# STM32F722xx register map
File version: 1.0
Registers are 32-bit, read-write, reset 0x0 unless marked. A register's access mark holds for its fields unless they carry their own. Offsets are from the block's base; [hi:lo] are bit positions; 'fields as' and 'values as' point back to an identical list.

## FMC
Base 0xA0000000
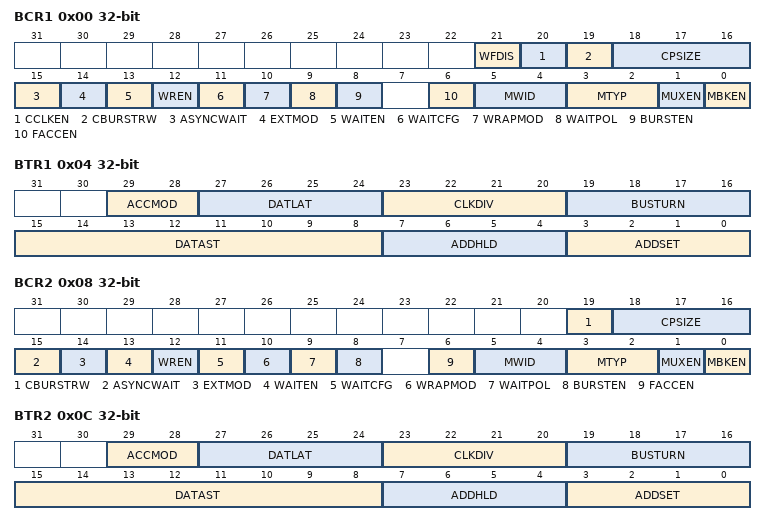
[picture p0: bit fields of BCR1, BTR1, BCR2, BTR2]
0x00 BCR1 — NOR/PSRAM chip-select control register(BCR) and chip-select timing register(BTR)
  [21] WFDIS — Write FIFO Disable
  [20] CCLKEN — Continuous clock enable
  [19] CBURSTRW — Write burst enable
  [18:16] CPSIZE — CRAM page size
  [15] ASYNCWAIT — Asynchronous wait
  [14] EXTMOD — Extended mode enable
  [13] WAITEN — Wait enable bit
  [12] WREN — Write enable bit
  [11] WAITCFG — Wait timing configuration
  [10] WRAPMOD — Wrapped burst mode support
  [9] WAITPOL — Wait signal polarity bit
  [8] BURSTEN — Burst enable bit
  [6] FACCEN — Flash access enable
  [5:4] MWID — MWID[1:0] bits (Memory data bus width)
  [3:2] MTYP — MTYP[1:0] bits (Memory type)
  [1] MUXEN — Address/data multiplexing enable bit
  [0] MBKEN — Memory bank enable bit
0x04 BTR1 — NOR/PSRAM chip-select control register(BCR) and chip-select timing register(BTR)
  [29:28] ACCMOD — ACCMOD[1:0] bits (Access mode)
  [27:24] DATLAT — DATLA[3:0] bits (Data latency)
  [23:20] CLKDIV — CLKDIV[3:0] bits (Clock divide ratio)
  [19:16] BUSTURN — BUSTURN[3:0] bits (Bus turnaround phase duration)
  [15:8] DATAST — DATAST [3:0] bits (Data-phase duration)
  [7:4] ADDHLD — ADDHLD[3:0] bits (Address-hold phase duration)
  [3:0] ADDSET — ADDSET[3:0] bits (Address setup phase duration)
0x08 BCR2 — NOR/PSRAM chip-select control register(BCR) and chip-select timing register(BTR)
  [19] CBURSTRW — Write burst enable
  [18:16] CPSIZE — CRAM page size
  [15] ASYNCWAIT — Asynchronous wait
  [14] EXTMOD — Extended mode enable
  [13] WAITEN — Wait enable bit
  [12] WREN — Write enable bit
  [11] WAITCFG — Wait timing configuration
  [10] WRAPMOD — Wrapped burst mode support
  [9] WAITPOL — Wait signal polarity bit
  [8] BURSTEN — Burst enable bit
  [6] FACCEN — Flash access enable
  [5:4] MWID — MWID[1:0] bits (Memory data bus width)
  [3:2] MTYP — MTYP[1:0] bits (Memory type)
  [1] MUXEN — Address/data multiplexing enable bit
  [0] MBKEN — Memory bank enable bit
0x0C BTR2 — NOR/PSRAM chip-select control register(BCR) and chip-select timing register(BTR)
  fields as BTR1
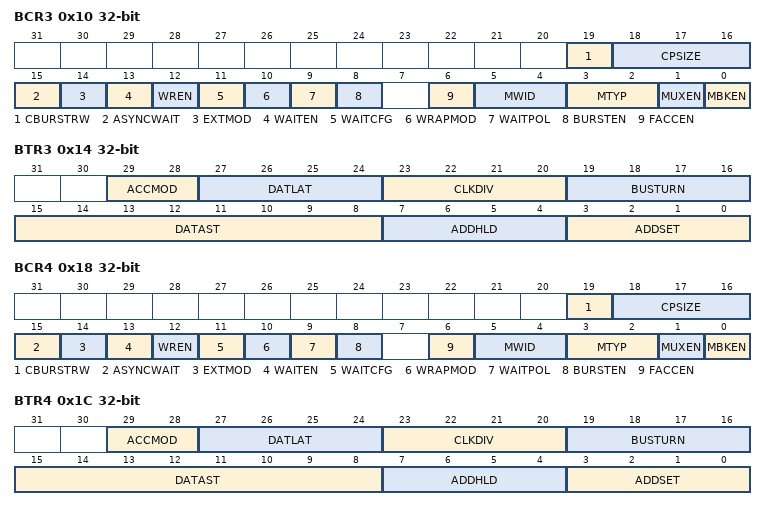
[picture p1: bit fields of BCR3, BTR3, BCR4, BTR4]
0x10 BCR3 — NOR/PSRAM chip-select control register(BCR) and chip-select timing register(BTR)
  fields as BCR2
0x14 BTR3 — NOR/PSRAM chip-select control register(BCR) and chip-select timing register(BTR)
  fields as BTR1
0x18 BCR4 — NOR/PSRAM chip-select control register(BCR) and chip-select timing register(BTR)
  fields as BCR2
0x1C BTR4 — NOR/PSRAM chip-select control register(BCR) and chip-select timing register(BTR)
  fields as BTR1
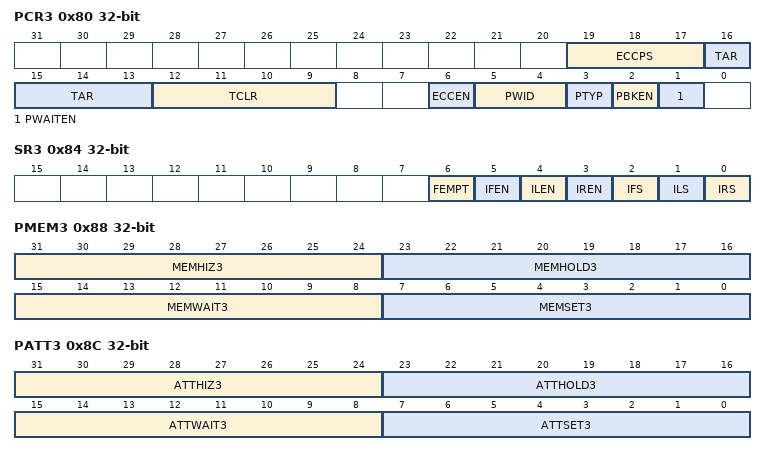
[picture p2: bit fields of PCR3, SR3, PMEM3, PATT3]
0x80 PCR3 — NAND Flash control register
  [19:17] ECCPS — ECCPS[2:0] bits (ECC page size)
  [16:13] TAR — TAR[3:0] bits (ALE to RE delay)
  [12:9] TCLR — TCLR[3:0] bits (CLE to RE delay)
  [6] ECCEN — ECC computation logic enable bit
  [5:4] PWID — PWID[1:0] bits (NAND Flash databus width)
  [3] PTYP — Memory type
  [2] PBKEN — PC Card/NAND Flash memory bank enable bit
  [1] PWAITEN — Wait feature enable bit
0x84 SR3 — NAND Flash FIFO status and interrupt register
  [6] FEMPT — FIFO empty
  [5] IFEN — Interrupt Falling Edge detection Enable bit
  [4] ILEN — Interrupt Level detection Enable bit
  [3] IREN — Interrupt Rising Edge detection Enable bit
  [2] IFS — Interrupt Falling Edge status
  [1] ILS — Interrupt Level status
  [0] IRS — Interrupt Rising Edge status
0x88 PMEM3 — NAND Flash Common memory space timing register
  [31:24] MEMHIZ3 — MEMHIZ3[7:0] bits (Common memory 3 databus HiZ time)
  [23:16] MEMHOLD3 — MEMHOLD3[7:0] bits (Common memory 3 hold time)
  [15:8] MEMWAIT3 — MEMWAIT3[7:0] bits (Common memory 3 wait time)
  [7:0] MEMSET3 — MEMSET3[7:0] bits (Common memory 3 setup time)
0x8C PATT3 — NAND Flash Attribute memory space timing register
  [31:24] ATTHIZ3 — ATTHIZ3[7:0] bits (Attribute memory 3 databus HiZ time)
  [23:16] ATTHOLD3 — ATTHOLD3[7:0] bits (Attribute memory 3 hold time)
  [15:8] ATTWAIT3 — ATTWAIT3[7:0] bits (Attribute memory 3 wait time)
  [7:0] ATTSET3 — ATTSET3[7:0] bits (Attribute memory 3 setup time)
0x94 ECCR3 — NAND Flash ECC result registers
  [31:0] ECC3 — ECC result
